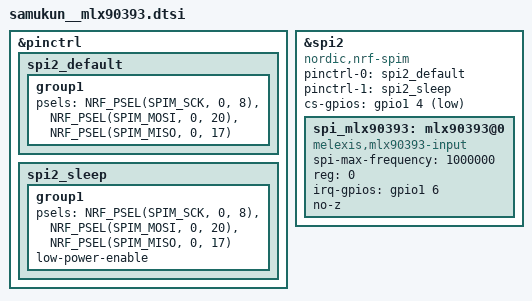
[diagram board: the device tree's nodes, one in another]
/*
 * Copyright (c) 2020 Pete Johanson
 *
 * SPDX-License-Identifier: MIT
 */

&pinctrl {
    spi2_default: spi2_default {
        group1 {
            psels = <NRF_PSEL(SPIM_SCK, 0, 8)>,
                    <NRF_PSEL(SPIM_MOSI, 0, 20)>,
                    <NRF_PSEL(SPIM_MISO, 0, 17)>;
        };
    };
    spi2_sleep: spi2_sleep {
        group1 {
            psels = <NRF_PSEL(SPIM_SCK, 0, 8)>,
                    <NRF_PSEL(SPIM_MOSI, 0, 20)>,
                    <NRF_PSEL(SPIM_MISO, 0, 17)>;
            low-power-enable;
        };
    };
};

#include <dt-bindings/spi/spi.h>
&spi2 {
    compatible = "nordic,nrf-spim";
    status = "okay";
    pinctrl-0 = <&spi2_default>;
    pinctrl-1 = <&spi2_sleep>;
    pinctrl-names = "default", "sleep";
    cs-gpios = <&gpio1 4 (GPIO_ACTIVE_LOW | GPIO_PULL_UP)>;
    spi_mlx90393: mlx90393@0 {
        compatible = "melexis,mlx90393-input";
        status = "okay";
        spi-max-frequency = <1000000>;
        reg = <0>;
        irq-gpios = <&gpio1 6 (GPIO_ACTIVE_HIGH | GPIO_PULL_DOWN)>;
        no-z;
    };
};

// &pinctrl {
//     i2c0_default: i2c0_default {
//         group1 {
//             psels = <NRF_PSEL(TWIM_SDA, 0, 9)>,
//                     <NRF_PSEL(TWIM_SCL, 0, 10)>;
//             bias-pull-up;
//         };
//     };
//     i2c0_sleep: i2c0_sleep {
//         group1 {
//             psels = <NRF_PSEL(TWIM_SDA, 0, 9)>,
//                     <NRF_PSEL(TWIM_SCL, 0, 10)>;
//             bias-pull-up;
//             low-power-enable;
//         };
//     };
// };

// &i2c0 {
//     status = "okay";
//     compatible = "nordic,nrf-twim";
//     pinctrl-0 = <&i2c0_default>;
//     pinctrl-1 = <&i2c0_sleep>;
//     pinctrl-names = "default", "sleep";
//     clock-frequency = <100000>;
//     i2c_mlx90393: mlx90393@c {
//         compatible = "melexis,mlx90393-input";
//         status = "okay";
//         reg = <0x0c>;
//         irq-gpios = <&gpio1 6 (GPIO_ACTIVE_HIGH | GPIO_PULL_DOWN)>;
//     };
// };
